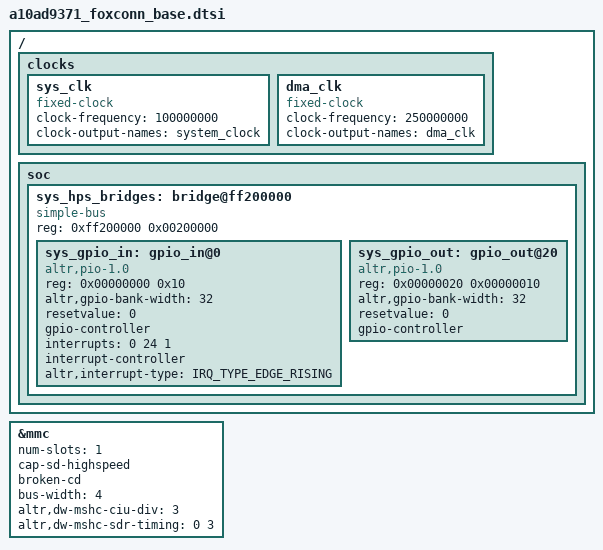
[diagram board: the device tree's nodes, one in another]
#include "socfpga_arria10_socdk.dtsi"

&mmc {
	status = "okay";
	num-slots = <1>;
	cap-sd-highspeed;
	broken-cd;
	bus-width = <4>;
	altr,dw-mshc-ciu-div = <3>;
	altr,dw-mshc-sdr-timing = <0 3>;
};

/ {
	clocks {
		sys_clk: sys_clk {
			#clock-cells = <0>;
			compatible = "fixed-clock";
			clock-frequency = <100000000>;
			clock-output-names = "system_clock";
		};

		dma_clk: dma_clk {
			#clock-cells = <0x0>;
			compatible = "fixed-clock";
			clock-frequency = <250000000>;
			clock-output-names = "dma_clk";
		};
	};

	soc {
		sys_hps_bridges: bridge@ff200000 {
			compatible = "simple-bus";
			reg = <0xff200000 0x00200000>;
			#address-cells = <1>;
			#size-cells = <1>;
			ranges = <0x00000000 0xff200000 0x00200000>;

			sys_gpio_in: gpio_in@0 {
	   			compatible = "altr,pio-1.0";
	   			reg = <0x00000000 0x10>;
				altr,gpio-bank-width = <32>;
				resetvalue = <0>;
	   			#gpio-cells = <2>;
	   			gpio-controller;

	   			interrupts = <0 24 1>;/* irq-type irq-number low-to-high-edge */
	   			interrupt-controller;
	   			#interrupt-cells = <1>;
	   			altr,interrupt-type = <IRQ_TYPE_EDGE_RISING>;
			};

			sys_gpio_out: gpio_out@20 {
				compatible = "altr,pio-1.0";
				reg = <0x00000020 0x00000010>;
				altr,gpio-bank-width = <32>;
				resetvalue = <0>;
				#gpio-cells = <2>;
				gpio-controller;
			};
		};
	};
};
